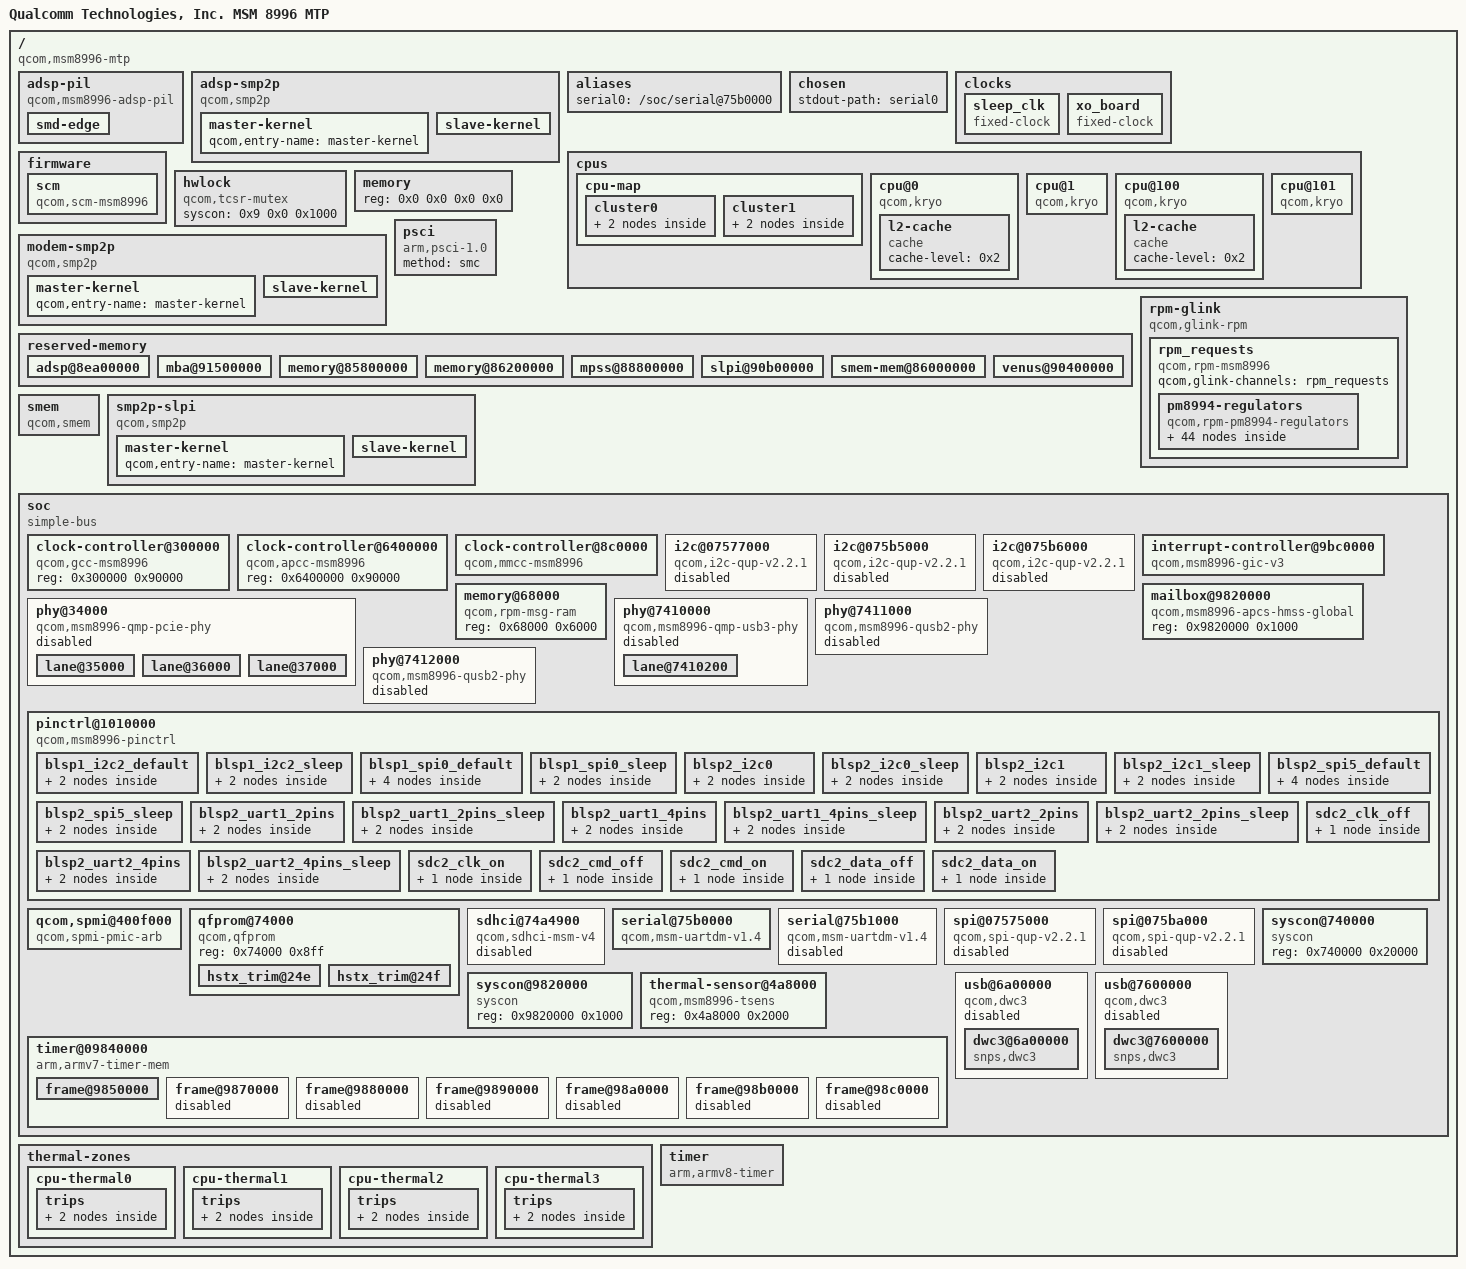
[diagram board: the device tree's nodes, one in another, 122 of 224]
/dts-v1/;

/ {
	#address-cells = <0x2>;
	#size-cells = <0x2>;
	compatible = "qcom,msm8996-mtp";
	interrupt-parent = <0x1>;
	model = "Qualcomm Technologies, Inc. MSM 8996 MTP";

	__symbols__ {
		CPU0 = "/cpus/cpu@0";
		CPU1 = "/cpus/cpu@1";
		CPU2 = "/cpus/cpu@100";
		CPU3 = "/cpus/cpu@101";
		L2_0 = "/cpus/cpu@0/l2-cache";
		L2_1 = "/cpus/cpu@100/l2-cache";
		adsp_region = "/reserved-memory/adsp@8ea00000";
		adsp_smp2p_in = "/adsp-smp2p/slave-kernel";
		adsp_smp2p_out = "/adsp-smp2p/master-kernel";
		apcs = "/soc/syscon@9820000";
		apcs_glb = "/soc/mailbox@9820000";
		blsp1_i2c2 = "/soc/i2c@07577000";
		blsp1_i2c2_default = "/soc/pinctrl@1010000/blsp1_i2c2_default";
		blsp1_i2c2_sleep = "/soc/pinctrl@1010000/blsp1_i2c2_sleep";
		blsp1_spi0 = "/soc/spi@07575000";
		blsp1_spi0_default = "/soc/pinctrl@1010000/blsp1_spi0_default";
		blsp1_spi0_sleep = "/soc/pinctrl@1010000/blsp1_spi0_sleep";
		blsp2_i2c0 = "/soc/i2c@075b5000";
		blsp2_i2c0_default = "/soc/pinctrl@1010000/blsp2_i2c0";
		blsp2_i2c0_sleep = "/soc/pinctrl@1010000/blsp2_i2c0_sleep";
		blsp2_i2c1 = "/soc/i2c@075b6000";
		blsp2_i2c1_default = "/soc/pinctrl@1010000/blsp2_i2c1";
		blsp2_i2c1_sleep = "/soc/pinctrl@1010000/blsp2_i2c1_sleep";
		blsp2_spi5 = "/soc/spi@075ba000";
		blsp2_spi5_default = "/soc/pinctrl@1010000/blsp2_spi5_default";
		blsp2_spi5_sleep = "/soc/pinctrl@1010000/blsp2_spi5_sleep";
		blsp2_uart1 = "/soc/serial@75b0000";
		blsp2_uart1_2pins_default = "/soc/pinctrl@1010000/blsp2_uart1_2pins";
		blsp2_uart1_2pins_sleep = "/soc/pinctrl@1010000/blsp2_uart1_2pins_sleep";
		blsp2_uart1_4pins_default = "/soc/pinctrl@1010000/blsp2_uart1_4pins";
		blsp2_uart1_4pins_sleep = "/soc/pinctrl@1010000/blsp2_uart1_4pins_sleep";
		blsp2_uart2 = "/soc/serial@75b1000";
		blsp2_uart2_2pins_default = "/soc/pinctrl@1010000/blsp2_uart2_2pins";
		blsp2_uart2_2pins_sleep = "/soc/pinctrl@1010000/blsp2_uart2_2pins_sleep";
		blsp2_uart2_4pins_default = "/soc/pinctrl@1010000/blsp2_uart2_4pins";
		blsp2_uart2_4pins_sleep = "/soc/pinctrl@1010000/blsp2_uart2_4pins_sleep";
		cpu_alert0 = "/thermal-zones/cpu-thermal0/trips/trip0";
		cpu_alert1 = "/thermal-zones/cpu-thermal1/trips/trip0";
		cpu_alert2 = "/thermal-zones/cpu-thermal2/trips/trip0";
		cpu_alert3 = "/thermal-zones/cpu-thermal3/trips/trip0";
		cpu_crit0 = "/thermal-zones/cpu-thermal0/trips/trip1";
		cpu_crit1 = "/thermal-zones/cpu-thermal1/trips/trip1";
		cpu_crit2 = "/thermal-zones/cpu-thermal2/trips/trip1";
		cpu_crit3 = "/thermal-zones/cpu-thermal3/trips/trip1";
		gcc = "/soc/clock-controller@300000";
		hsusb_phy1 = "/soc/phy@7411000";
		hsusb_phy2 = "/soc/phy@7412000";
		intc = "/soc/interrupt-controller@9bc0000";
		kryocc = "/soc/clock-controller@6400000";
		mba_region = "/reserved-memory/mba@91500000";
		mmcc = "/soc/clock-controller@8c0000";
		modem_smp2p_in = "/modem-smp2p/slave-kernel";
		modem_smp2p_out = "/modem-smp2p/master-kernel";
		mpss_region = "/reserved-memory/mpss@88800000";
		msmgpio = "/soc/pinctrl@1010000";
		pciephy_0 = "/soc/phy@34000/lane@35000";
		pciephy_1 = "/soc/phy@34000/lane@36000";
		pciephy_2 = "/soc/phy@34000/lane@37000";
		pm8994_l1 = "/rpm-glink/rpm_requests/pm8994-regulators/l1";
		pm8994_l10 = "/rpm-glink/rpm_requests/pm8994-regulators/l10";
		pm8994_l11 = "/rpm-glink/rpm_requests/pm8994-regulators/l11";
		pm8994_l12 = "/rpm-glink/rpm_requests/pm8994-regulators/l12";
		pm8994_l13 = "/rpm-glink/rpm_requests/pm8994-regulators/l13";
		pm8994_l14 = "/rpm-glink/rpm_requests/pm8994-regulators/l14";
		pm8994_l15 = "/rpm-glink/rpm_requests/pm8994-regulators/l15";
		pm8994_l16 = "/rpm-glink/rpm_requests/pm8994-regulators/l16";
		pm8994_l17 = "/rpm-glink/rpm_requests/pm8994-regulators/l17";
		pm8994_l18 = "/rpm-glink/rpm_requests/pm8994-regulators/l18";
		pm8994_l19 = "/rpm-glink/rpm_requests/pm8994-regulators/l19";
		pm8994_l2 = "/rpm-glink/rpm_requests/pm8994-regulators/l2";
		pm8994_l20 = "/rpm-glink/rpm_requests/pm8994-regulators/l20";
		pm8994_l21 = "/rpm-glink/rpm_requests/pm8994-regulators/l21";
		pm8994_l22 = "/rpm-glink/rpm_requests/pm8994-regulators/l22";
		pm8994_l23 = "/rpm-glink/rpm_requests/pm8994-regulators/l23";
		pm8994_l24 = "/rpm-glink/rpm_requests/pm8994-regulators/l24";
		pm8994_l25 = "/rpm-glink/rpm_requests/pm8994-regulators/l25";
		pm8994_l26 = "/rpm-glink/rpm_requests/pm8994-regulators/l26";
		pm8994_l27 = "/rpm-glink/rpm_requests/pm8994-regulators/l27";
		pm8994_l28 = "/rpm-glink/rpm_requests/pm8994-regulators/l28";
		pm8994_l29 = "/rpm-glink/rpm_requests/pm8994-regulators/l29";
		pm8994_l3 = "/rpm-glink/rpm_requests/pm8994-regulators/l3";
		pm8994_l30 = "/rpm-glink/rpm_requests/pm8994-regulators/l30";
		pm8994_l31 = "/rpm-glink/rpm_requests/pm8994-regulators/l31";
		pm8994_l32 = "/rpm-glink/rpm_requests/pm8994-regulators/l32";
		pm8994_l4 = "/rpm-glink/rpm_requests/pm8994-regulators/l4";
		pm8994_l5 = "/rpm-glink/rpm_requests/pm8994-regulators/l5";
		pm8994_l6 = "/rpm-glink/rpm_requests/pm8994-regulators/l6";
		pm8994_l7 = "/rpm-glink/rpm_requests/pm8994-regulators/l7";
		pm8994_l8 = "/rpm-glink/rpm_requests/pm8994-regulators/l8";
		pm8994_l9 = "/rpm-glink/rpm_requests/pm8994-regulators/l9";
		pm8994_s1 = "/rpm-glink/rpm_requests/pm8994-regulators/s1";
		pm8994_s10 = "/rpm-glink/rpm_requests/pm8994-regulators/s10";
		pm8994_s11 = "/rpm-glink/rpm_requests/pm8994-regulators/s11";
		pm8994_s12 = "/rpm-glink/rpm_requests/pm8994-regulators/s12";
		pm8994_s2 = "/rpm-glink/rpm_requests/pm8994-regulators/s2";
		pm8994_s3 = "/rpm-glink/rpm_requests/pm8994-regulators/s3";
		pm8994_s4 = "/rpm-glink/rpm_requests/pm8994-regulators/s4";
		pm8994_s5 = "/rpm-glink/rpm_requests/pm8994-regulators/s5";
		pm8994_s6 = "/rpm-glink/rpm_requests/pm8994-regulators/s6";
		pm8994_s7 = "/rpm-glink/rpm_requests/pm8994-regulators/s7";
		pm8994_s8 = "/rpm-glink/rpm_requests/pm8994-regulators/s8";
		pm8994_s9 = "/rpm-glink/rpm_requests/pm8994-regulators/s9";
		qusb2p_hstx_trim = "/soc/qfprom@74000/hstx_trim@24e";
		qusb2s_hstx_trim = "/soc/qfprom@74000/hstx_trim@24f";
		rpm_msg_ram = "/soc/memory@68000";
		sdc2_clk_off = "/soc/pinctrl@1010000/sdc2_clk_off";
		sdc2_clk_on = "/soc/pinctrl@1010000/sdc2_clk_on";
		sdc2_cmd_off = "/soc/pinctrl@1010000/sdc2_cmd_off";
		sdc2_cmd_on = "/soc/pinctrl@1010000/sdc2_cmd_on";
		sdc2_data_off = "/soc/pinctrl@1010000/sdc2_data_off";
		sdc2_data_on = "/soc/pinctrl@1010000/sdc2_data_on";
		sdhc2 = "/soc/sdhci@74a4900";
		sleep_clk = "/clocks/sleep_clk";
		slpi_region = "/reserved-memory/slpi@90b00000";
		slpi_smp2p_in = "/smp2p-slpi/slave-kernel";
		slpi_smp2p_out = "/smp2p-slpi/master-kernel";
		smem_mem = "/reserved-memory/smem-mem@86000000";
		soc = "/soc";
		spmi_bus = "/soc/qcom,spmi@400f000";
		ssusb_phy_0 = "/soc/phy@7410000/lane@7410200";
		tcsr_mutex = "/hwlock";
		tcsr_mutex_regs = "/soc/syscon@740000";
		tsens0 = "/soc/thermal-sensor@4a8000";
		usb2 = "/soc/usb@7600000";
		usb3 = "/soc/usb@6a00000";
		venus_region = "/reserved-memory/venus@90400000";
		xo_board = "/clocks/xo_board";
	};

	adsp-pil {
		clock-names = "xo";
		clocks = <0x19>;
		compatible = "qcom,msm8996-adsp-pil";
		interrupt-names = "wdog", "fatal", "ready", "handover", "stop-ack";
		interrupts-extended = <0x1 0x0 0xa2 0x1 0x23 0x0 0x1 0x23 0x1 0x1 0x23 0x2 0x1 0x23 0x3 0x1>;
		memory-region = <0x24>;
		qcom,smem-state-names = "stop";
		qcom,smem-states = <0x25 0x0>;

		smd-edge {
			interrupts = <0x0 0x9c 0x1>;
			label = "lpass";
			qcom,ipc = <0x26 0x10 0x8>;
			qcom,remote-pid = <0x2>;
			qcom,smd-edge = <0x1>;
		};
	};

	adsp-smp2p {
		compatible = "qcom,smp2p";
		interrupts = <0x0 0x9e 0x1>;
		qcom,ipc = <0x26 0x10 0xa>;
		qcom,local-pid = <0x0>;
		qcom,remote-pid = <0x2>;
		qcom,smem = <0x1bb 0x1ad>;

		master-kernel {
			#qcom,smem-state-cells = <0x1>;
			phandle = <0x25>;
			qcom,entry-name = "master-kernel";
		};

		slave-kernel {
			#interrupt-cells = <0x2>;
			interrupt-controller;
			phandle = <0x23>;
			qcom,entry-name = "slave-kernel";
		};
	};

	aliases {
		serial0 = "/soc/serial@75b0000";
	};

	chosen {
		stdout-path = "serial0";
	};

	clocks {

		sleep_clk {
			#clock-cells = <0x0>;
			clock-frequency = <0x7ffc>;
			clock-output-names = "sleep_clk";
			compatible = "fixed-clock";
			phandle = <0x33>;
		};

		xo_board {
			#clock-cells = <0x0>;
			clock-frequency = <0x124f800>;
			clock-output-names = "xo_board";
			compatible = "fixed-clock";
			phandle = <0x19>;
		};
	};

	cpus {
		#address-cells = <0x2>;
		#size-cells = <0x0>;

		cpu-map {

			cluster0 {

				core0 {
					cpu = <0x4>;
				};

				core1 {
					cpu = <0x5>;
				};
			};

			cluster1 {

				core0 {
					cpu = <0x6>;
				};

				core1 {
					cpu = <0x7>;
				};
			};
		};

		cpu@0 {
			compatible = "qcom,kryo";
			device_type = "cpu";
			enable-method = "psci";
			next-level-cache = <0x2>;
			phandle = <0x4>;
			reg = <0x0 0x0>;

			l2-cache {
				cache-level = <0x2>;
				compatible = "cache";
				phandle = <0x2>;
			};
		};

		cpu@1 {
			compatible = "qcom,kryo";
			device_type = "cpu";
			enable-method = "psci";
			next-level-cache = <0x2>;
			phandle = <0x5>;
			reg = <0x0 0x1>;
		};

		cpu@100 {
			compatible = "qcom,kryo";
			device_type = "cpu";
			enable-method = "psci";
			next-level-cache = <0x3>;
			phandle = <0x6>;
			reg = <0x0 0x100>;

			l2-cache {
				cache-level = <0x2>;
				compatible = "cache";
				phandle = <0x3>;
			};
		};

		cpu@101 {
			compatible = "qcom,kryo";
			device_type = "cpu";
			enable-method = "psci";
			next-level-cache = <0x3>;
			phandle = <0x7>;
			reg = <0x0 0x101>;
		};
	};

	firmware {

		scm {
			compatible = "qcom,scm-msm8996";
		};
	};

	hwlock {
		#hwlock-cells = <0x1>;
		compatible = "qcom,tcsr-mutex";
		phandle = <0xb>;
		syscon = <0x9 0x0 0x1000>;
	};

	memory {
		device_type = "memory";
		reg = <0x0 0x0 0x0 0x0>;
	};

	modem-smp2p {
		compatible = "qcom,smp2p";
		interrupts = <0x0 0x1c3 0x1>;
		qcom,ipc = <0x26 0x10 0xe>;
		qcom,local-pid = <0x0>;
		qcom,remote-pid = <0x1>;
		qcom,smem = <0x1b3 0x1ac>;

		master-kernel {
			#qcom,smem-state-cells = <0x1>;
			phandle = <0x7c>;
			qcom,entry-name = "master-kernel";
		};

		slave-kernel {
			#interrupt-cells = <0x2>;
			interrupt-controller;
			phandle = <0x7d>;
			qcom,entry-name = "slave-kernel";
		};
	};

	psci {
		compatible = "arm,psci-1.0";
		method = "smc";
	};

	reserved-memory {
		#address-cells = <0x2>;
		#size-cells = <0x2>;
		ranges;

		adsp@8ea00000 {
			no-map;
			phandle = <0x24>;
			reg = <0x0 0x8ea00000 0x0 0x1a00000>;
		};

		mba@91500000 {
			no-map;
			phandle = <0x27>;
			reg = <0x0 0x91500000 0x0 0x200000>;
		};

		memory@85800000 {
			no-map;
			reg = <0x0 0x85800000 0x0 0x800000>;
		};

		memory@86200000 {
			no-map;
			reg = <0x0 0x86200000 0x0 0x2600000>;
		};

		mpss@88800000 {
			no-map;
			phandle = <0x2a>;
			reg = <0x0 0x88800000 0x0 0x6200000>;
		};

		slpi@90b00000 {
			no-map;
			phandle = <0x28>;
			reg = <0x0 0x90b00000 0x0 0xa00000>;
		};

		smem-mem@86000000 {
			no-map;
			phandle = <0xa>;
			reg = <0x0 0x86000000 0x0 0x200000>;
		};

		venus@90400000 {
			no-map;
			phandle = <0x29>;
			reg = <0x0 0x90400000 0x0 0x700000>;
		};
	};

	rpm-glink {
		compatible = "qcom,glink-rpm";
		interrupts = <0x0 0xa8 0x1>;
		mboxes = <0xd 0x0>;
		qcom,rpm-msg-ram = <0xc>;

		rpm_requests {
			compatible = "qcom,rpm-msm8996";
			qcom,glink-channels = "rpm_requests";

			pm8994-regulators {
				compatible = "qcom,rpm-pm8994-regulators";

				l1 {
					phandle = <0x40>;
				};

				l10 {
					phandle = <0x49>;
				};

				l11 {
					phandle = <0x4a>;
				};

				l12 {
					phandle = <0x1c>;
				};

				l13 {
					phandle = <0x4b>;
				};

				l14 {
					phandle = <0x4c>;
				};

				l15 {
					phandle = <0x4d>;
				};

				l16 {
					phandle = <0x4e>;
				};

				l17 {
					phandle = <0x4f>;
				};

				l18 {
					phandle = <0x50>;
				};

				l19 {
					phandle = <0x51>;
				};

				l2 {
					phandle = <0x41>;
				};

				l20 {
					phandle = <0x52>;
				};

				l21 {
					phandle = <0x53>;
				};

				l22 {
					phandle = <0x54>;
				};

				l23 {
					phandle = <0x55>;
				};

				l24 {
					phandle = <0x1d>;
				};

				l25 {
					phandle = <0x56>;
				};

				l26 {
					phandle = <0x57>;
				};

				l27 {
					phandle = <0x58>;
				};

				l28 {
					phandle = <0x1b>;
				};

				l29 {
					phandle = <0x59>;
				};

				l3 {
					phandle = <0x42>;
				};

				l30 {
					phandle = <0x5a>;
				};

				l31 {
					phandle = <0x5b>;
				};

				l32 {
					phandle = <0x5c>;
				};

				l4 {
					phandle = <0x43>;
				};

				l5 {
					phandle = <0x44>;
				};

				l6 {
					phandle = <0x45>;
				};

				l7 {
					phandle = <0x46>;
				};

				l8 {
					phandle = <0x47>;
				};

				l9 {
					phandle = <0x48>;
				};

				s1 {
					phandle = <0x34>;
				};

				s10 {
					phandle = <0x3d>;
				};

				s11 {
					phandle = <0x3e>;
				};

				s12 {
					phandle = <0x3f>;
				};

				s2 {
					phandle = <0x35>;
				};

				s3 {
					phandle = <0x36>;
				};

				s4 {
					phandle = <0x37>;
				};

				s5 {
					phandle = <0x38>;
				};

				s6 {
					phandle = <0x39>;
				};

				s7 {
					phandle = <0x3a>;
				};

				s8 {
					phandle = <0x3b>;
				};

				s9 {
					phandle = <0x3c>;
				};
			};
		};
	};

	smem {
		compatible = "qcom,smem";
		hwlocks = <0xb 0x3>;
		memory-region = <0xa>;
	};

	smp2p-slpi {
		compatible = "qcom,smp2p";
		interrupts = <0x0 0xb2 0x1>;
		qcom,ipc = <0x26 0x10 0x1a>;
		qcom,local-pid = <0x0>;
		qcom,remote-pid = <0x3>;
		qcom,smem = <0x1e1 0x1ae>;

		master-kernel {
			#qcom,smem-state-cells = <0x1>;
			phandle = <0x7f>;
			qcom,entry-name = "master-kernel";
		};

		slave-kernel {
			#interrupt-cells = <0x2>;
			interrupt-controller;
			phandle = <0x7e>;
			qcom,entry-name = "slave-kernel";
		};
	};

	soc {
		#address-cells = <0x1>;
		#size-cells = <0x1>;
		compatible = "simple-bus";
		phandle = <0x5d>;
		ranges = <0x0 0x0 0x0 0xffffffff>;

		clock-controller@300000 {
			#clock-cells = <0x1>;
			#power-domain-cells = <0x1>;
			#reset-cells = <0x1>;
			compatible = "qcom,gcc-msm8996";
			phandle = <0xe>;
			reg = <0x300000 0x90000>;
		};

		clock-controller@6400000 {
			#clock-cells = <0x1>;
			compatible = "qcom,apcc-msm8996";
			phandle = <0x5e>;
			reg = <0x6400000 0x90000>;
		};

		clock-controller@8c0000 {
			#clock-cells = <0x1>;
			#power-domain-cells = <0x1>;
			#reset-cells = <0x1>;
			assigned-clock-rates = <0x25317c00 0x30479e80 0x3a699d00 0x39387000 0x312c8040>;
			assigned-clocks = <0x1a 0xf 0x1a 0x3 0x1a 0x7 0x1a 0x9 0x1a 0xb>;
			compatible = "qcom,mmcc-msm8996";
			phandle = <0x1a>;
			reg = <0x8c0000 0x40000>;
		};

		i2c@07577000 {
			#address-cells = <0x1>;
			#size-cells = <0x0>;
			clock-names = "iface", "core";
			clocks = <0xe 0x6d 0xe 0x76>;
			compatible = "qcom,i2c-qup-v2.2.1";
			interrupts = <0x0 0x61 0x0>;
			phandle = <0x64>;
			pinctrl-0 = <0x15>;
			pinctrl-1 = <0x16>;
			pinctrl-names = "default", "sleep";
			reg = <0x7577000 0x1000>;
			status = "disabled";
		};

		i2c@075b5000 {
			#address-cells = <0x1>;
			#size-cells = <0x0>;
			clock-names = "iface", "core";
			clocks = <0xe 0x81 0xe 0x84>;
			compatible = "qcom,i2c-qup-v2.2.1";
			interrupts = <0x0 0x65 0x0>;
			phandle = <0x60>;
			pinctrl-0 = <0x11>;
			pinctrl-1 = <0x12>;
			pinctrl-names = "default", "sleep";
			reg = <0x75b5000 0x1000>;
			status = "disabled";
		};

		i2c@075b6000 {
			#address-cells = <0x1>;
			#size-cells = <0x0>;
			clock-names = "iface", "core";
			clocks = <0xe 0x81 0xe 0x87>;
			compatible = "qcom,i2c-qup-v2.2.1";
			interrupts = <0x0 0x66 0x0>;
			phandle = <0x62>;
			pinctrl-0 = <0x13>;
			pinctrl-1 = <0x14>;
			pinctrl-names = "default", "sleep";
			reg = <0x75b6000 0x1000>;
			status = "disabled";
		};

		interrupt-controller@9bc0000 {
			#interrupt-cells = <0x3>;
			#redistributor-regions = <0x1>;
			compatible = "qcom,msm8996-gic-v3", "arm,gic-v3";
			interrupt-controller;
			interrupts = <0x1 0x9 0x4>;
			phandle = <0x1>;
			redistributor-stride = <0x0 0x40000>;
			reg = <0x9bc0000 0x10000 0x9c00000 0x100000>;
		};

		mailbox@9820000 {
			#mbox-cells = <0x1>;
			compatible = "qcom,msm8996-apcs-hmss-global";
			phandle = <0xd>;
			reg = <0x9820000 0x1000>;
		};

		memory@68000 {
			compatible = "qcom,rpm-msg-ram";
			phandle = <0xc>;
			reg = <0x68000 0x6000>;
		};

		phy@34000 {
			#address-cells = <0x1>;
			#clock-cells = <0x1>;
			#size-cells = <0x1>;
			clock-names = "aux", "cfg_ahb", "ref";
			clocks = <0xe 0xc0 0xe 0xbf 0xe 0xd8>;
			compatible = "qcom,msm8996-qmp-pcie-phy";
			ranges;
			reg = <0x34000 0x488>;
			reset-names = "phy", "common", "cfg";
			resets = <0xe 0x55 0xe 0x65 0xe 0x66>;
			status = "disabled";
			vdda-phy-supply = <0x1b>;
			vdda-pll-supply = <0x1c>;

			lane@35000 {
				#phy-cells = <0x0>;
				clock-names = "pipe0";
				clock-output-names = "pcie_0_pipe_clk_src";
				clocks = <0xe 0xb4>;
				phandle = <0x77>;
				reg = <0x35000 0x130 0x35200 0x200 0x35400 0x1dc>;
				reset-names = "lane0";
				resets = <0xe 0x50>;
			};

			lane@36000 {
				#phy-cells = <0x0>;
				clock-names = "pipe1";
				clock-output-names = "pcie_1_pipe_clk_src";
				clocks = <0xe 0xb9>;
				phandle = <0x78>;
				reg = <0x36000 0x130 0x36200 0x200 0x36400 0x1dc>;
				reset-names = "lane1";
				resets = <0xe 0x52>;
			};

			lane@37000 {
				#phy-cells = <0x0>;
				clock-names = "pipe2";
				clock-output-names = "pcie_2_pipe_clk_src";
				clocks = <0xe 0xbe>;
				phandle = <0x79>;
				reg = <0x37000 0x130 0x37200 0x200 0x37400 0x1dc>;
				reset-names = "lane2";
				resets = <0xe 0x54>;
			};
		};

		phy@7410000 {
			#address-cells = <0x1>;
			#clock-cells = <0x1>;
			#size-cells = <0x1>;
			clock-names = "aux", "cfg_ahb", "ref";
			clocks = <0xe 0x5e 0xe 0x63 0xe 0xd5>;
			compatible = "qcom,msm8996-qmp-usb3-phy";
			ranges;
			reg = <0x7410000 0x1c4>;
			reset-names = "phy", "common";
			resets = <0xe 0x67 0xe 0x68>;
			status = "disabled";
			vdda-phy-supply = <0x1b>;
			vdda-pll-supply = <0x1c>;

			lane@7410200 {
				#phy-cells = <0x0>;
				clock-names = "pipe0";
				clock-output-names = "usb3_phy_pipe_clk_src";
				clocks = <0xe 0x5f>;
				phandle = <0x22>;
				reg = <0x7410200 0x200 0x7410400 0x130 0x7410600 0x1a8>;
			};
		};

		phy@7411000 {
			#phy-cells = <0x0>;
			clock-names = "cfg_ahb", "ref";
			clocks = <0xe 0x63 0xe 0xda>;
			compatible = "qcom,msm8996-qusb2-phy";
			nvmem-cells = <0x1e>;
			phandle = <0x21>;
			reg = <0x7411000 0x180>;
			resets = <0xe 0x9>;
			status = "disabled";
			vdda-phy-dpdm-supply = <0x1d>;
			vdda-pll-supply = <0x1c>;
		};

		phy@7412000 {
			#phy-cells = <0x0>;
			clock-names = "cfg_ahb", "ref";
			clocks = <0xe 0x63 0xe 0xd9>;
			compatible = "qcom,msm8996-qusb2-phy";
			nvmem-cells = <0x1f>;
			phandle = <0x20>;
			reg = <0x7412000 0x180>;
			resets = <0xe 0xa>;
			status = "disabled";
			vdda-phy-dpdm-supply = <0x1d>;
			vdda-pll-supply = <0x1c>;
		};

		pinctrl@1010000 {
			#gpio-cells = <0x2>;
			#interrupt-cells = <0x2>;
			compatible = "qcom,msm8996-pinctrl";
			gpio-controller;
			interrupt-controller;
			interrupts = <0x0 0xd0 0x4>;
			phandle = <0x67>;
			reg = <0x1010000 0x300000>;

			blsp1_i2c2_default {
				phandle = <0x15>;

				pinconf {
					bias-disable = <0x0>;
					drive-strength = <0x10>;
					pins = "gpio47", "gpio48";
				};

				pinmux {
					function = "blsp_i2c3";
					pins = "gpio47", "gpio48";
				};
			};

			blsp1_i2c2_sleep {
				phandle = <0x16>;

				pinconf {
					bias-disable = <0x0>;
					drive-strength = <0x2>;
					pins = "gpio47", "gpio48";
				};

				pinmux {
					function = "gpio";
					pins = "gpio47", "gpio48";
				};
			};

			blsp1_spi0_default {
				phandle = <0xf>;

				pinconf {
					bias-disable;
					drive-strength = <0xc>;
					pins = "gpio0", "gpio1", "gpio3";
				};

				pinconf_cs {
					bias-disable;
					drive-strength = <0x10>;
					output-high;
					pins = "gpio2";
				};

				pinmux {
					function = "blsp_spi1";
					pins = "gpio0", "gpio1", "gpio3";
				};

				pinmux_cs {
					function = "gpio";
					pins = "gpio2";
				};
			};

			blsp1_spi0_sleep {
				phandle = <0x10>;

				pinconf {
					bias-pull-down;
					drive-strength = <0x2>;
					pins = "gpio0", "gpio1", "gpio2", "gpio3";
				};

				pinmux {
					function = "gpio";
					pins = "gpio0", "gpio1", "gpio2", "gpio3";
				};
			};

			blsp2_i2c0 {
				phandle = <0x11>;

				pinconf {
					bias-disable;
					drive-strength = <0x10>;
					pins = "gpio55", "gpio56";
				};

				pinmux {
					function = "blsp_i2c7";
					pins = "gpio55", "gpio56";
				};
			};

			blsp2_i2c0_sleep {
				phandle = <0x12>;

				pinconf {
					bias-disable;
					drive-strength = <0x2>;
					pins = "gpio55", "gpio56";
				};

				pinmux {
					function = "gpio";
					pins = "gpio55", "gpio56";
				};
			};

			blsp2_i2c1 {
				phandle = <0x13>;

				pinconf {
					bias-disable;
					drive-strength = <0x10>;
					pins = "gpio6", "gpio7";
				};

				pinmux {
					function = "blsp_i2c8";
					pins = "gpio6", "gpio7";
				};
			};

			blsp2_i2c1_sleep {
				phandle = <0x14>;

				pinconf {
					bias-disable;
					drive-strength = <0x2>;
					pins = "gpio6", "gpio7";
				};

				pinmux {
					function = "gpio";
					pins = "gpio6", "gpio7";
				};
			};

			blsp2_spi5_default {
				phandle = <0x17>;

				pinconf {
					bias-disable;
					drive-strength = <0xc>;
					pins = "gpio85", "gpio86", "gpio88";
				};

				pinconf_cs {
					bias-disable;
					drive-strength = <0x10>;
					output-high;
					pins = "gpio87";
				};

				pinmux {
					function = "blsp_spi12";
					pins = "gpio85", "gpio86", "gpio88";
				};

				pinmux_cs {
					function = "gpio";
					pins = "gpio87";
				};
			};

			blsp2_spi5_sleep {
				phandle = <0x18>;

				pinconf {
					bias-pull-down;
					drive-strength = <0x2>;
					pins = "gpio85", "gpio86", "gpio87", "gpio88";
				};

				pinmux {
					function = "gpio";
					pins = "gpio85", "gpio86", "gpio87", "gpio88";
				};
			};

			blsp2_uart1_2pins {
				phandle = <0x68>;

				pinconf {
					bias-disable;
					drive-strength = <0x10>;
					pins = "gpio4", "gpio5";
				};

				pinmux {
					function = "blsp_uart8";
					pins = "gpio4", "gpio5";
				};
			};

			blsp2_uart1_2pins_sleep {
				phandle = <0x69>;

				pinconf {
					bias-disable;
					drive-strength = <0x2>;
					pins = "gpio4", "gpio5";
				};

				pinmux {
					function = "gpio";
					pins = "gpio4", "gpio5";
				};
			};

			blsp2_uart1_4pins {
				phandle = <0x6a>;

				pinconf {
					bias-disable;
					drive-strength = <0x10>;
					pins = "gpio4", "gpio5", "gpio6", "gpio7";
				};

				pinmux {
					function = "blsp_uart8";
					pins = "gpio4", "gpio5", "gpio6", "gpio7";
				};
			};

			blsp2_uart1_4pins_sleep {
				phandle = <0x6b>;

				pinconf {
					bias-disable;
					drive-strength = <0x2>;
					pins = "gpio4", "gpiio5", "gpio6", "gpio7";
				};

				pinmux {
					function = "gpio";
					pins = "gpio4", "gpio5", "gpio6", "gpio7";
				};
			};

			blsp2_uart2_2pins {
				phandle = <0x6c>;

				pinconf {
					bias-disable;
					drive-strength = <0x10>;
					pins = "gpio49", "gpio50";
				};

				pinmux {
					function = "blsp_uart9";
					pins = "gpio49", "gpio50";
				};
			};

			blsp2_uart2_2pins_sleep {
				phandle = <0x6d>;

				pinconf {
					bias-disable;
					drive-strength = <0x2>;
					pins = "gpio49", "gpio50";
				};

				pinmux {
					function = "gpio";
					pins = "gpio49", "gpio50";
				};
			};

			blsp2_uart2_4pins {
				phandle = <0x6e>;

				pinconf {
					bias-disable;
					drive-strength = <0x10>;
					pins = "gpio49", "gpio50", "gpio51", "gpio52";
				};

				pinmux {
					function = "blsp_uart9";
					pins = "gpio49", "gpio50", "gpio51", "gpio52";
				};
			};

			blsp2_uart2_4pins_sleep {
				phandle = <0x6f>;

				pinconf {
					bias-disable;
					drive-strength = <0x2>;
					pins = "gpio49", "gpio50", "gpio51", "gpio52";
				};

				pinmux {
					function = "gpio";
					pins = "gpio49", "gpio50", "gpio51", "gpio52";
				};
			};

			sdc2_clk_off {
				phandle = <0x71>;

				config {
					bias-disable;
					drive-strength = <0x2>;
					pins = "sdc2_clk";
				};
			};

			sdc2_clk_on {
				phandle = <0x70>;

				config {
					bias-disable;
					drive-strength = <0x10>;
					pins = "sdc2_clk";
				};
			};

			sdc2_cmd_off {
				phandle = <0x73>;

				config {
					bias-pull-up;
					drive-strength = <0x2>;
					pins = "sdc2_cmd";
				};
			};

			sdc2_cmd_on {
				phandle = <0x72>;

				config {
					bias-pull-up;
					drive-strength = <0xa>;
					pins = "sdc2_cmd";
				};
			};

			sdc2_data_off {
				phandle = <0x75>;

				config {
					bias-pull-up;
					drive-strength = <0x2>;
					pins = "sdc2_data";
				};
			};

			sdc2_data_on {
				phandle = <0x74>;

				config {
					bias-pull-up;
					drive-strength = <0xa>;
					pins = "sdc2_data";
				};
			};
		};

		qcom,spmi@400f000 {
			#address-cells = <0x2>;
			#interrupt-cells = <0x4>;
			#size-cells = <0x0>;
			compatible = "qcom,spmi-pmic-arb";
			interrupt-controller;
			interrupt-names = "periph_irq";
			interrupts = <0x0 0x146 0x4>;
			phandle = <0x76>;
			qcom,channel = <0x0>;
			qcom,ee = <0x0>;
			reg = <0x400f000 0x1000 0x4400000 0x800000 0x4c00000 0x800000 0x5800000 0x200000 0x400a000 0x2100>;
			reg-names = "core", "chnls", "obsrvr", "intr", "cnfg";
		};

		qfprom@74000 {
			#address-cells = <0x1>;
			#size-cells = <0x1>;
			compatible = "qcom,qfprom";
			reg = <0x74000 0x8ff>;

			hstx_trim@24e {
				bits = <0x5 0x4>;
				phandle = <0x1e>;
				reg = <0x24e 0x2>;
			};

			hstx_trim@24f {
				bits = <0x1 0x4>;
				phandle = <0x1f>;
				reg = <0x24f 0x1>;
			};
		};

		sdhci@74a4900 {
			bus-width = <0x4>;
			clock-names = "iface", "core", "xo";
			clocks = <0xe 0x68 0xe 0x67 0x19>;
			compatible = "qcom,sdhci-msm-v4";
			interrupt-names = "hc_irq", "pwr_irq";
			interrupts = <0x0 0x7d 0x0 0x0 0xdd 0x0>;
			phandle = <0x66>;
			reg = <0x74a4900 0x314 0x74a4000 0x800>;
			reg-names = "hc_mem", "core_mem";
			status = "disabled";
		};

		serial@75b0000 {
			clock-names = "core", "iface";
			clocks = <0xe 0x88 0xe 0x81>;
			compatible = "qcom,msm-uartdm-v1.4", "qcom,msm-uartdm";
			interrupts = <0x0 0x72 0x4>;
			phandle = <0x61>;
			reg = <0x75b0000 0x1000>;
			status = "okay";
		};

		serial@75b1000 {
			clock-names = "core", "iface";
			clocks = <0xe 0x8b 0xe 0x81>;
			compatible = "qcom,msm-uartdm-v1.4", "qcom,msm-uartdm";
			interrupts = <0x0 0x73 0x4>;
			phandle = <0x63>;
			reg = <0x75b1000 0x1000>;
			status = "disabled";
		};

		spi@07575000 {
			#address-cells = <0x1>;
			#size-cells = <0x0>;
			clock-names = "core", "iface";
			clocks = <0xe 0x6f 0xe 0x6d>;
			compatible = "qcom,spi-qup-v2.2.1";
			interrupts = <0x0 0x5f 0x4>;
			phandle = <0x5f>;
			pinctrl-0 = <0xf>;
			pinctrl-1 = <0x10>;
			pinctrl-names = "default", "sleep";
			reg = <0x7575000 0x600>;
			status = "disabled";
		};

		spi@075ba000 {
			#address-cells = <0x1>;
			#size-cells = <0x0>;
			clock-names = "core", "iface";
			clocks = <0xe 0x92 0xe 0x81>;
			compatible = "qcom,spi-qup-v2.2.1";
			interrupts = <0x0 0x6a 0x4>;
			phandle = <0x65>;
			pinctrl-0 = <0x17>;
			pinctrl-1 = <0x18>;
			pinctrl-names = "default", "sleep";
			reg = <0x75ba000 0x600>;
			status = "disabled";
		};

		syscon@740000 {
			compatible = "syscon";
			phandle = <0x9>;
			reg = <0x740000 0x20000>;
		};

		syscon@9820000 {
			compatible = "syscon";
			phandle = <0x26>;
			reg = <0x9820000 0x1000>;
		};

		thermal-sensor@4a8000 {
			#thermal-sensor-cells = <0x1>;
			compatible = "qcom,msm8996-tsens";
			phandle = <0x8>;
			reg = <0x4a8000 0x2000>;
		};

		timer@09840000 {
			#address-cells = <0x1>;
			#size-cells = <0x1>;
			clock-frequency = <0x124f800>;
			compatible = "arm,armv7-timer-mem";
			ranges;
			reg = <0x9840000 0x1000>;

			frame@9850000 {
				frame-number = <0x0>;
				interrupts = <0x0 0x1f 0x4 0x0 0x1e 0x4>;
				reg = <0x9850000 0x1000 0x9860000 0x1000>;
			};

			frame@9870000 {
				frame-number = <0x1>;
				interrupts = <0x0 0x20 0x4>;
				reg = <0x9870000 0x1000>;
				status = "disabled";
			};

			frame@9880000 {
				frame-number = <0x2>;
				interrupts = <0x0 0x21 0x4>;
				reg = <0x9880000 0x1000>;
				status = "disabled";
			};

			frame@9890000 {
				frame-number = <0x3>;
				interrupts = <0x0 0x22 0x4>;
				reg = <0x9890000 0x1000>;
				status = "disabled";
			};

			frame@98a0000 {
				frame-number = <0x4>;
				interrupts = <0x0 0x23 0x4>;
				reg = <0x98a0000 0x1000>;
				status = "disabled";
			};

			frame@98b0000 {
				frame-number = <0x5>;
				interrupts = <0x0 0x24 0x4>;
				reg = <0x98b0000 0x1000>;
				status = "disabled";
			};

			frame@98c0000 {
				frame-number = <0x6>;
				interrupts = <0x0 0x25 0x4>;
				reg = <0x98c0000 0x1000>;
				status = "disabled";
			};
		};

		usb@6a00000 {
			#address-cells = <0x1>;
			#size-cells = <0x1>;
			assigned-clock-rates = <0x124f800 0x7270e00>;
			assigned-clocks = <0xe 0x5d 0xe 0x5b>;
			clocks = <0xe 0x51 0xe 0x5b 0xe 0xd2 0xe 0x5d 0xe 0x5c 0xe 0x63>;
			compatible = "qcom,dwc3";
			phandle = <0x7b>;
			power-domains = <0xe 0x4>;
			ranges;
			status = "disabled";

			dwc3@6a00000 {
				compatible = "snps,dwc3";
				interrupts = <0x0 0x83 0x0>;
				phy-names = "usb2-phy", "usb3-phy";
				phys = <0x21 0x22>;
				reg = <0x6a00000 0xcc00>;
				snps,dis_enblslpm_quirk;
				snps,dis_u2_susphy_quirk;
			};
		};

		usb@7600000 {
			#address-cells = <0x1>;
			#size-cells = <0x1>;
			assigned-clock-rates = <0x124f800 0x3938700>;
			assigned-clocks = <0xe 0x62 0xe 0x60>;
			clocks = <0xe 0x55 0xe 0x60 0xe 0x62 0xe 0x61 0xe 0x63>;
			compatible = "qcom,dwc3";
			phandle = <0x7a>;
			power-domains = <0xe 0x4>;
			ranges;
			status = "disabled";

			dwc3@7600000 {
				compatible = "snps,dwc3";
				interrupts = <0x0 0x8a 0x0>;
				phy-names = "usb2-phy";
				phys = <0x20>;
				reg = <0x7600000 0xcc00>;
				snps,dis_enblslpm_quirk;
				snps,dis_u2_susphy_quirk;
			};
		};
	};

	thermal-zones {

		cpu-thermal0 {
			polling-delay = <0x3e8>;
			polling-delay-passive = <0xfa>;
			thermal-sensors = <0x8 0x3>;

			trips {

				trip0 {
					hysteresis = <0x7d0>;
					phandle = <0x2b>;
					temperature = <0x124f8>;
					type = "passive";
				};

				trip1 {
					hysteresis = <0x7d0>;
					phandle = <0x2c>;
					temperature = <0x1adb0>;
					type = "critical";
				};
			};
		};

		cpu-thermal1 {
			polling-delay = <0x3e8>;
			polling-delay-passive = <0xfa>;
			thermal-sensors = <0x8 0x5>;

			trips {

				trip0 {
					hysteresis = <0x7d0>;
					phandle = <0x2d>;
					temperature = <0x124f8>;
					type = "passive";
				};

				trip1 {
					hysteresis = <0x7d0>;
					phandle = <0x2e>;
					temperature = <0x1adb0>;
					type = "critical";
				};
			};
		};

		cpu-thermal2 {
			polling-delay = <0x3e8>;
			polling-delay-passive = <0xfa>;
			thermal-sensors = <0x8 0x8>;

			trips {

				trip0 {
					hysteresis = <0x7d0>;
					phandle = <0x2f>;
					temperature = <0x124f8>;
					type = "passive";
				};

				trip1 {
					hysteresis = <0x7d0>;
					phandle = <0x30>;
					temperature = <0x1adb0>;
					type = "critical";
				};
			};
		};

		cpu-thermal3 {
			polling-delay = <0x3e8>;
			polling-delay-passive = <0xfa>;
			thermal-sensors = <0x8 0xa>;

			trips {

				trip0 {
					hysteresis = <0x7d0>;
					phandle = <0x31>;
					temperature = <0x124f8>;
					type = "passive";
				};

				trip1 {
					hysteresis = <0x7d0>;
					phandle = <0x32>;
					temperature = <0x1adb0>;
					type = "critical";
				};
			};
		};
	};

	timer {
		compatible = "arm,armv8-timer";
		interrupts = <0x1 0xd 0xf08 0x1 0xe 0xf08 0x1 0xb 0xf08 0x1 0xa 0xf08>;
	};
};
